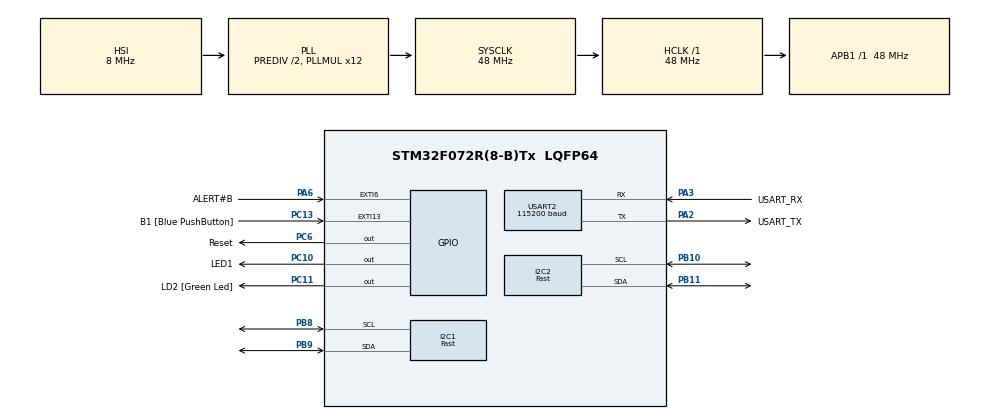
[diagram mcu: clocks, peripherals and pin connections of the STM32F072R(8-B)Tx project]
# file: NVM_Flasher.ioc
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I2C1.I2C_Speed_Mode=I2C_Fast
I2C1.Timing=0x0000020B
I2C2.I2C_Speed_Mode=I2C_Fast
I2C2.NoStretchMode=I2C_NOSTRETCH_DISABLE
I2C2.Speed=400
I2C2.Timing=0x2010091A
Mcu.Family=STM32F0
Mcu.Name=STM32F072R(8-B)Tx
Mcu.Package=LQFP64
NVIC.EXTI4_15_IRQn=true\:0\:0\:false\:false\:true\:true\:true
NVIC.USART2_IRQn=true\:0\:0\:false\:false\:true\:true\:true
PA13.GPIO_Label=TMS
PA13.Signal=SYS_SWDIO
PA14.GPIO_Label=TCK
PA14.Signal=SYS_SWCLK
PA2.GPIO_Label=USART_TX
PA2.GPIO_Mode=GPIO_MODE_AF_PP
PA2.GPIO_PuPd=GPIO_NOPULL
PA2.GPIO_Speed=GPIO_SPEED_FREQ_LOW
PA2.Mode=Asynchronous
PA2.Signal=USART2_TX
PA3.GPIO_Label=USART_RX
PA3.GPIO_Mode=GPIO_MODE_AF_PP
PA3.GPIO_PuPd=GPIO_NOPULL
PA3.GPIO_Speed=GPIO_SPEED_FREQ_LOW
PA3.Mode=Asynchronous
PA3.Signal=USART2_RX
PA6.GPIO_Label=ALERT\#B
PA6.Signal=GPXTI6
PB10.Mode=I2C
PB10.Signal=I2C2_SCL
PB11.Mode=I2C
PB11.Signal=I2C2_SDA
PB8.GPIO_FM8=__NULL
PB8.GPIO_PuPdOD=GPIO_PULLUP
PB8.GPIO_Speed=GPIO_SPEED_FREQ_MEDIUM
PB8.Mode=I2C
PB8.Signal=I2C1_SCL
PB9.GPIO_FM9=__NULL
PB9.GPIO_Speed=GPIO_SPEED_FREQ_MEDIUM
PB9.Mode=I2C
PB9.Signal=I2C1_SDA
PC10.GPIO_Label=LED1
PC10.Signal=GPIO_Output
PC11.GPIO_Label=LD2 [Green Led]
PC11.GPIO_ModeDefaultOutputPP=GPIO_MODE_OUTPUT_PP
PC11.GPIO_PuPd=GPIO_NOPULL
PC11.GPIO_Speed=GPIO_SPEED_FREQ_LOW
PC11.Signal=GPIO_Output
PC13.GPIO_Label=B1 [Blue PushButton]
PC13.GPIO_ModeDefaultEXTI=GPIO_MODE_EVT_FALLING
PC13.GPIO_PuPd=GPIO_NOPULL
PC13.Signal=GPXTI13
PC14-OSC32_IN.Signal=RCC_OSC32_IN
PC15-OSC32_OUT.Signal=RCC_OSC32_OUT
PC6.GPIO_Label=Reset
PC6.Signal=GPIO_Output
PF0-OSC_IN.Signal=RCC_OSC_IN
PF1-OSC_OUT.Signal=RCC_OSC_OUT
ProjectManager.HeapSize=0x200
ProjectManager.StackSize=0x400
ProjectManager.TargetToolchain=EWARM V8
RCC.AHBFreq_Value=48000000
RCC.APB1Freq_Value=48000000
RCC.APB1TimFreq_Value=48000000
RCC.FLatency-AdvancedSettings=FLASH_LATENCY_1
RCC.HCLKFreq_Value=48000000
RCC.PLLDivider=RCC_PREDIV_DIV2
RCC.PLLMUL=RCC_PLL_MUL12
RCC.SYSCLKFreq_VALUE=48000000
RCC.SYSCLKSource=RCC_SYSCLKSOURCE_PLLCLK
USART2.BaudRate=115200
USART2.VirtualMode-Asynchronous=VM_ASYNC
USART2.WordLength=WORDLENGTH_8B
board=NUCLEO-F072RB

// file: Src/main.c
/* USER CODE BEGIN Header */
/**
  ******************************************************************************
  * @file           : main.c
  * @brief          : Main program body
  ******************************************************************************
  * @attention
  *
  * <h2><center>&copy; Copyright (c) 2019 STMicroelectronics.
  * All rights reserved.</center></h2>
  *
  * This software component is licensed by ST under BSD 3-Clause license,
  * the "License"; You may not use this file except in compliance with the
  * License. You may obtain a copy of the License at:
  *                        opensource.org/licenses/BSD-3-Clause
  *
  ******************************************************************************
  */
/* USER CODE END Header */

#include "main.h"
#include "i2c.h"
#include "usart.h"
#include "gpio.h"

/* USER CODE BEGIN Includes */
#include "main_NVM.h"
/* USER CODE END Includes */

void SystemClock_Config(void);

int main(void)
{

  /* MCU Configuration--------------------------------------------------------*/

  /* Reset of all peripherals, Initializes the Flash interface and the Systick. */
  HAL_Init();

  /* Configure the system clock */
  SystemClock_Config();

  /* Initialize all configured peripherals */
  MX_GPIO_Init();
  MX_I2C1_Init();
  MX_I2C2_Init();
  MX_USART2_UART_Init();

  /* USER CODE BEGIN 2 */
  main_NVM();
  /* USER CODE END 2 */

  /* Infinite loop */
  while (1)
  {

  }
}

void SystemClock_Config(void)
{
  RCC_OscInitTypeDef RCC_OscInitStruct = {0};
  RCC_ClkInitTypeDef RCC_ClkInitStruct = {0};
  RCC_PeriphCLKInitTypeDef PeriphClkInit = {0};

  /** Initializes the CPU, AHB and APB busses clocks
  */
  RCC_OscInitStruct.OscillatorType = RCC_OSCILLATORTYPE_HSI;
  RCC_OscInitStruct.HSIState = RCC_HSI_ON;
  RCC_OscInitStruct.HSICalibrationValue = RCC_HSICALIBRATION_DEFAULT;
  RCC_OscInitStruct.PLL.PLLState = RCC_PLL_ON;
  RCC_OscInitStruct.PLL.PLLSource = RCC_PLLSOURCE_HSI;
  RCC_OscInitStruct.PLL.PLLMUL = RCC_PLL_MUL12;
  RCC_OscInitStruct.PLL.PREDIV = RCC_PREDIV_DIV2;
  if (HAL_RCC_OscConfig(&RCC_OscInitStruct) != HAL_OK)
  {
    Error_Handler();
  }
  /** Initializes the CPU, AHB and APB busses clocks
  */
  RCC_ClkInitStruct.ClockType = RCC_CLOCKTYPE_HCLK|RCC_CLOCKTYPE_SYSCLK
                              |RCC_CLOCKTYPE_PCLK1;
  RCC_ClkInitStruct.SYSCLKSource = RCC_SYSCLKSOURCE_PLLCLK;
  RCC_ClkInitStruct.AHBCLKDivider = RCC_SYSCLK_DIV1;
  RCC_ClkInitStruct.APB1CLKDivider = RCC_HCLK_DIV1;

  if (HAL_RCC_ClockConfig(&RCC_ClkInitStruct, FLASH_LATENCY_1) != HAL_OK)
  {
    Error_Handler();
  }
  PeriphClkInit.PeriphClockSelection = RCC_PERIPHCLK_USART2|RCC_PERIPHCLK_I2C1;
  PeriphClkInit.Usart2ClockSelection = RCC_USART2CLKSOURCE_PCLK1;
  PeriphClkInit.I2c1ClockSelection = RCC_I2C1CLKSOURCE_HSI;
  if (HAL_RCCEx_PeriphCLKConfig(&PeriphClkInit) != HAL_OK)
  {
    Error_Handler();
  }
}

void Error_Handler(void)
{
}

/************************ (C) COPYRIGHT STMicroelectronics *****END OF FILE****/
